VERSION ""

NS_ :

BS_:

BU_:
VAL_TABLE_ vtLight 7 "light_Not_Available" 6 "light_Fault_Detected" 1 "light_Activated" 0 "light_De_activated" ;
VAL_TABLE_ FMI 22 "Data Drifted Low" 21 "Data Drifted High" 20 "Received Network Data In Error" 0 "Above normal (most severe)" 1 "Below normal (most severe)" 2 "Data erratic" 3 "Voltage above normal" 4 "Voltage below normal" 5 "Current below normal" 6 "Current above normal" 7 "Mechanical system not responding" 8 "Abnormal frequency" 9 "Abnormal update rate" 10 "Abnormal rate of change" 11 "Root cause not known" 12 "Bad intelligent device" 13 "Out of calibration" 14 "Special intstructions" 15 "Above normal (least severe)" 16 "Above normal (moderately severe)" 17 "Below normal (least severe)" 18 "Below normal (moderately severe)" 19 "Received network data in error" 31 "Condition Exists" ;

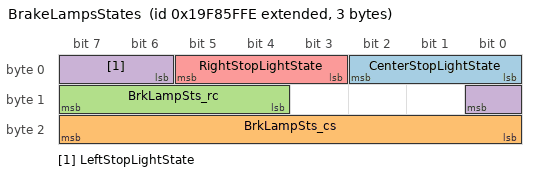
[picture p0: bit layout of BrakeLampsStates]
BO_ 2583191550 BrakeLampsStates: 3 Vector__XXX
 SG_ CenterStopLightState : 0|3@1+ (1,0) [0|7] "" Vector__XXX
 SG_ BrkLampSts_cs : 16|8@1+ (1,0) [0|255] "" Vector__XXX
 SG_ BrkLampSts_rc : 12|4@1+ (1,0) [0|15] "" Vector__XXX
 SG_ LeftStopLightState : 6|3@1+ (1,0) [0|7] "" Vector__XXX
 SG_ RightStopLightState : 3|3@1+ (1,0) [0|7] "" Vector__XXX

CM_ "$File: //depot/auto/dbc/Software_Modules/Exterior_Lights/ELS_ext/0.1.1.0/ELS_ext.dbc $
$Change: 215974 $
$DateTime: 2024/08/21 10:04:46 $
$Revision: #1 $";
BA_DEF_  "DBName" STRING ;
BA_DEF_ SG_  "SigType" ENUM  "Default","Range","RangeSigned","ASCII","Discrete","Control","ReferencePGN","DTC","StringDelimiter","StringLength","StringLengthControl","MessageCounter","MessageChecksum";
BA_DEF_ SG_  "GenSigSendType" ENUM  "Cyclic","OnWrite","OnWriteWithRepetition","OnChange","OnChangeWithRepetition","IfActive","IfActiveWithRepetition","NoSigSendType";
BA_DEF_ SG_  "GenSigILSupport" ENUM  "No","Yes";
BA_DEF_ SG_  "GenSigEVName" STRING ;
BA_DEF_ BO_  "GenMsgILSupport" ENUM  "No","Yes";
BA_DEF_ BO_  "GenMsgDelayTime" INT 0 1000;
BA_DEF_ BO_  "GenMsgRequestable" INT 0 1;
BA_DEF_ BO_  "GenMsgSendType" ENUM  "cyclic","NotUsed","NotUsed","NotUsed","NotUsed","NotUsed","NotUsed","IfActive","noMsgSendType";
BA_DEF_ BO_  "VFrameFormat" ENUM  "StandardCAN","ExtendedCAN","reserved","J1939PG";
BA_DEF_ BO_  "GenMsgCycleTime" INT 0 3600000;
BA_DEF_ BU_  "NmStationAddress" INT 0 255;
BA_DEF_  "SAE_J1939_DA_SpecVersion" STRING ;
BA_DEF_  "SAE_J1939_81_SpecVersion" STRING ;
BA_DEF_  "DatabaseVersion" STRING ;
BA_DEF_  "BusType" STRING ;
BA_DEF_  "ProtocolType" STRING ;
BA_DEF_  "SAE_J1939_75_SpecVersion" STRING ;
BA_DEF_  "SAE_J1939_21_SpecVersion" STRING ;
BA_DEF_  "SAE_J1939_73_SpecVersion" STRING ;
BA_DEF_  "SAE_J1939_71_SpecVersion" STRING ;
BA_DEF_ BO_  "Producer" STRING ;
BA_DEF_DEF_  "DBName" "";
BA_DEF_DEF_  "SigType" "Default";
BA_DEF_DEF_  "GenSigSendType" "NoSigSendType";
BA_DEF_DEF_  "GenSigILSupport" "Yes";
BA_DEF_DEF_  "GenSigEVName" "Env@Nodename_@Signame";
BA_DEF_DEF_  "GenMsgILSupport" "Yes";
BA_DEF_DEF_  "GenMsgDelayTime" 0;
BA_DEF_DEF_  "GenMsgRequestable" 1;
BA_DEF_DEF_  "GenMsgSendType" "noMsgSendType";
BA_DEF_DEF_  "VFrameFormat" "J1939PG";
BA_DEF_DEF_  "GenMsgCycleTime" 0;
BA_DEF_DEF_  "NmStationAddress" 254;
BA_DEF_DEF_  "SAE_J1939_DA_SpecVersion" "";
BA_DEF_DEF_  "SAE_J1939_81_SpecVersion" "";
BA_DEF_DEF_  "DatabaseVersion" "";
BA_DEF_DEF_  "BusType" "";
BA_DEF_DEF_  "ProtocolType" "";
BA_DEF_DEF_  "SAE_J1939_75_SpecVersion" "";
BA_DEF_DEF_  "SAE_J1939_21_SpecVersion" "";
BA_DEF_DEF_  "SAE_J1939_73_SpecVersion" "";
BA_DEF_DEF_  "SAE_J1939_71_SpecVersion" "";
BA_ "SAE_J1939_DA_SpecVersion" "2015-01";
BA_ "SAE_J1939_81_SpecVersion" "2012-05";
BA_ "DatabaseVersion" "8.5";
BA_ "BusType" "CAN";
BA_ "ProtocolType" "J1939";
BA_ "SAE_J1939_75_SpecVersion" "2012-05";
BA_ "SAE_J1939_21_SpecVersion" "2006-10";
BA_ "SAE_J1939_73_SpecVersion" "2012-10";
BA_ "SAE_J1939_71_SpecVersion" "2012-10";
BA_ "DBName" "HMI_ELS";
BA_ "GenMsgDelayTime" BO_ 2583191550 100;
BA_ "GenMsgCycleTime" BO_ 2583191550 100;
BA_ "GenMsgSendType" BO_ 2583191550 0;
BA_ "SigType" SG_ 2583191550 BrkLampSts_cs 12;
BA_ "SigType" SG_ 2583191550 BrkLampSts_rc 11;
BA_ "Producer" BO_ 2583191550 "ELS";
VAL_ 2583191550 CenterStopLightState 7 "light_Not_Available" 6 "light_Fault_Detected" 1 "light_Activated" 0 "light_De_activated" ;
VAL_ 2583191550 LeftStopLightState 7 "light_Not_Available" 6 "light_Fault_Detected" 1 "light_Activated" 0 "light_De_activated" ;
VAL_ 2583191550 RightStopLightState 7 "light_Not_Available" 6 "light_Fault_Detected" 1 "light_Activated" 0 "light_De_activated" ;
